# ATSAMC21N18A register map
Registers are 32-bit, access not given, no defined reset value unless marked. A register's access mark holds for its fields unless they carry their own. Addresses are absolute; registers are grouped by the start of their names; [hi:lo] are bit positions; {n}, {i} and the like mark numbered series; 'fields as' and 'values as' point back to an identical list.

## TC7
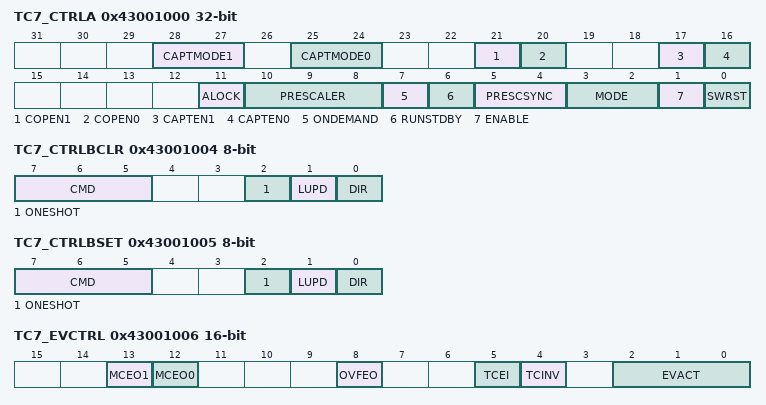
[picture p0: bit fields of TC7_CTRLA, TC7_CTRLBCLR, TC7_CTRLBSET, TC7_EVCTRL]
0x43001000 TC7_CTRLA — Control A
  [28:27] CAPTMODE1, [25:24] CAPTMODE0, [21] COPEN1, [20] COPEN0, [17] CAPTEN1, [16] CAPTEN0, [11] ALOCK, [10:8] PRESCALER, [7] ONDEMAND, [6] RUNSTDBY, [5:4] PRESCSYNC, [3:2] MODE, [1] ENABLE, [0] SWRST
0x43001004 TC7_CTRLBCLR 8-bit — Control B Clear
  [7:5] CMD, [2] ONESHOT, [1] LUPD, [0] DIR
0x43001005 TC7_CTRLBSET 8-bit — Control B Set
  [7:5] CMD, [2] ONESHOT, [1] LUPD, [0] DIR
0x43001006 TC7_EVCTRL 16-bit — Event Control
  [13] MCEO1, [12] MCEO0, [8] OVFEO, [5] TCEI, [4] TCINV, [2:0] EVACT
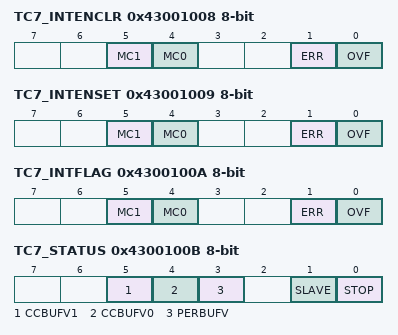
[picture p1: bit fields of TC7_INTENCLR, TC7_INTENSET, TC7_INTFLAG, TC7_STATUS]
0x43001008 TC7_INTENCLR 8-bit — Interrupt Enable Clear
  [5] MC1, [4] MC0, [1] ERR, [0] OVF
0x43001009 TC7_INTENSET 8-bit — Interrupt Enable Set
  [5] MC1, [4] MC0, [1] ERR, [0] OVF
0x4300100A TC7_INTFLAG 8-bit — Interrupt Flag Status and Clear
  [5] MC1, [4] MC0, [1] ERR, [0] OVF
0x4300100B TC7_STATUS 8-bit — Status
  [5] CCBUFV1, [4] CCBUFV0, [3] PERBUFV, [1] SLAVE, [0] STOP
0x4300100C TC7_WAVE 8-bit — Waveform Generation Control
  [1:0] WAVEGEN
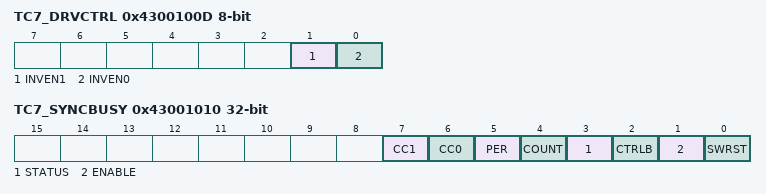
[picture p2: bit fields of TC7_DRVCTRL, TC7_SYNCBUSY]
0x4300100D TC7_DRVCTRL 8-bit — Control C
  [1] INVEN1, [0] INVEN0
0x4300100F TC7_DBGCTRL 8-bit — Debug Control
  [0] DBGRUN
0x43001010 TC7_SYNCBUSY — Synchronization Status
  [7] CC1, [6] CC0, [5] PER, [4] COUNT, [3] STATUS, [2] CTRLB, [1] ENABLE, [0] SWRST
0x43001014 TC7_COUNT_COUNT8 8-bit — COUNT8 Count
  [7:0] COUNT — Counter Value
0x43001014 TC7_COUNT_COUNT16 16-bit — COUNT16 Count
  [15:0] COUNT — Counter Value
0x43001014 TC7_COUNT_COUNT32 — COUNT32 Count
  [31:0] COUNT — Counter Value
0x4300101B TC7_PER_COUNT8 8-bit — COUNT8 Period
  [7:0] PER — Period Value
0x4300101C TC7_CC_COUNT8 8-bit — COUNT8 Compare and Capture
  [7:0] CC — Counter/Compare Value
0x4300101C TC7_CC_COUNT16 16-bit — COUNT16 Compare and Capture
  [15:0] CC — Counter/Compare Value
0x4300101C TC7_CC_COUNT32 — COUNT32 Compare and Capture
  [31:0] CC — Counter/Compare Value
0x4300102F TC7_PERBUF_COUNT8 8-bit — COUNT8 Period Buffer
  [7:0] PERBUF — Period Buffer Value
0x43001030 TC7_CCBUF_COUNT8 8-bit — COUNT8 Compare and Capture Buffer
  [7:0] CCBUF — Counter/Compare Buffer Value
0x43001030 TC7_CCBUF_COUNT16 16-bit — COUNT16 Compare and Capture Buffer
  [15:0] CCBUF — Counter/Compare Buffer Value
0x43001030 TC7_CCBUF_COUNT32 — COUNT32 Compare and Capture Buffer
  [31:0] CCBUF — Counter/Compare Buffer Value

## TCC0
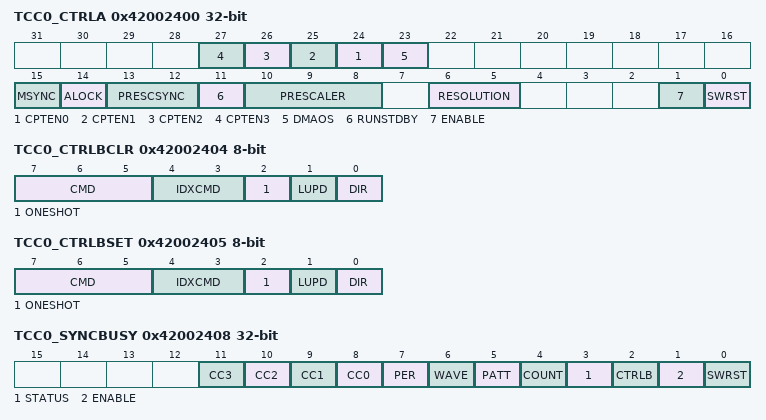
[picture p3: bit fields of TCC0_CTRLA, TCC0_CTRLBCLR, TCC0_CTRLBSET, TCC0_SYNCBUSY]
0x42002400 TCC0_CTRLA — Control A
  [n+24] CPTEN{n} (n=0..3), [23] DMAOS, [15] MSYNC, [14] ALOCK, [13:12] PRESCSYNC, [11] RUNSTDBY, [10:8] PRESCALER, [6:5] RESOLUTION, [1] ENABLE, [0] SWRST
0x42002404 TCC0_CTRLBCLR 8-bit — Control B Clear
  [7:5] CMD, [4:3] IDXCMD, [2] ONESHOT, [1] LUPD, [0] DIR
0x42002405 TCC0_CTRLBSET 8-bit — Control B Set
  [7:5] CMD, [4:3] IDXCMD, [2] ONESHOT, [1] LUPD, [0] DIR
0x42002408 TCC0_SYNCBUSY — Synchronization Busy
  [n+8] CC{n} (n=0..3), [7] PER, [6] WAVE, [5] PATT, [4] COUNT, [3] STATUS, [2] CTRLB, [1] ENABLE, [0] SWRST
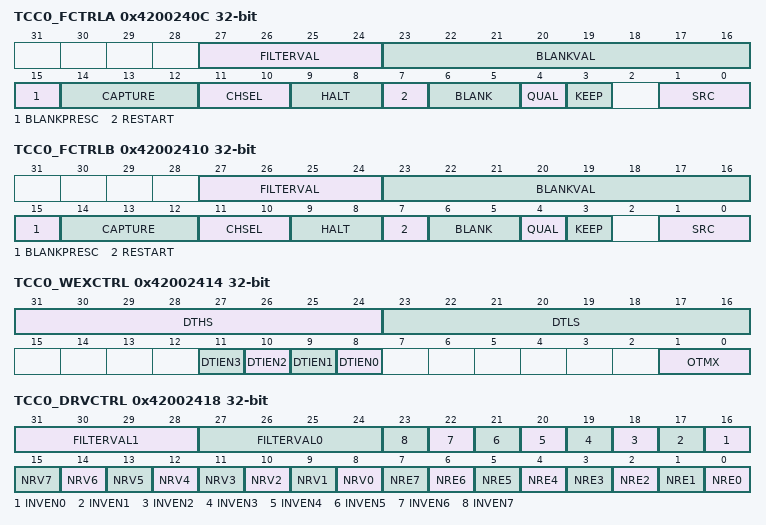
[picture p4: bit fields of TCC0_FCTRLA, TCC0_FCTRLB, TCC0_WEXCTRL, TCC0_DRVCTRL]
0x4200240C TCC0_FCTRLA — Recoverable Fault A Configuration
  [27:24] FILTERVAL, [23:16] BLANKVAL, [15] BLANKPRESC, [14:12] CAPTURE, [11:10] CHSEL, [9:8] HALT, [7] RESTART, [6:5] BLANK, [4] QUAL, [3] KEEP, [1:0] SRC
0x42002410 TCC0_FCTRLB — Recoverable Fault B Configuration
  fields as TCC0_FCTRLA
0x42002414 TCC0_WEXCTRL — Waveform Extension Configuration
  [31:24] DTHS, [23:16] DTLS, [n+8] DTIEN{n} (n=0..3), [1:0] OTMX
0x42002418 TCC0_DRVCTRL — Driver Control
  [31:28] FILTERVAL1, [27:24] FILTERVAL0, [n+16] INVEN{n} (n=0..7), [n+8] NRV{n} (n=0..7), [n] NRE{n} (n=0..7)
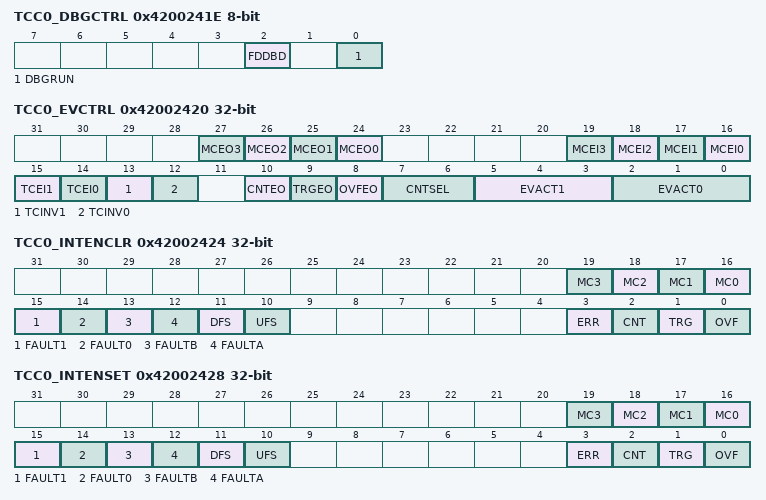
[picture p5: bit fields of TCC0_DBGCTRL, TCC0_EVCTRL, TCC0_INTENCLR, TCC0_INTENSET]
0x4200241E TCC0_DBGCTRL 8-bit — Debug Control
  [2] FDDBD, [0] DBGRUN
0x42002420 TCC0_EVCTRL — Event Control
  [n+24] MCEO{n} (n=0..3), [n+16] MCEI{n} (n=0..3), [15] TCEI1, [14] TCEI0, [13] TCINV1, [12] TCINV0, [10] CNTEO, [9] TRGEO, [8] OVFEO, [7:6] CNTSEL, [5:3] EVACT1, [2:0] EVACT0
0x42002424 TCC0_INTENCLR — Interrupt Enable Clear
  [n+16] MC{n} (n=0..3), [15] FAULT1, [14] FAULT0, [13] FAULTB, [12] FAULTA, [11] DFS, [10] UFS, [3] ERR, [2] CNT, [1] TRG, [0] OVF
0x42002428 TCC0_INTENSET — Interrupt Enable Set
  fields as TCC0_INTENCLR
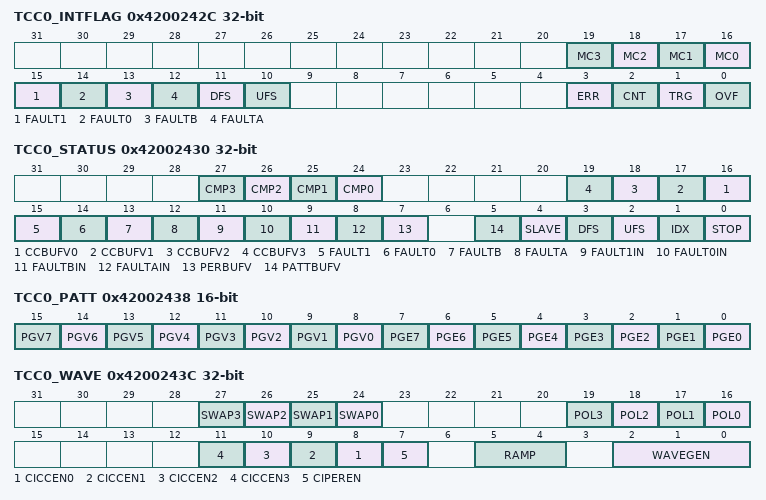
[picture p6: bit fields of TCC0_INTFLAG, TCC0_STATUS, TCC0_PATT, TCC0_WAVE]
0x4200242C TCC0_INTFLAG — Interrupt Flag Status and Clear
  fields as TCC0_INTENCLR
0x42002430 TCC0_STATUS — Status
  [n+24] CMP{n} (n=0..3), [n+16] CCBUFV{n} (n=0..3), [15] FAULT1, [14] FAULT0, [13] FAULTB, [12] FAULTA, [11] FAULT1IN, [10] FAULT0IN, [9] FAULTBIN, [8] FAULTAIN, [7] PERBUFV, [5] PATTBUFV, [4] SLAVE, [3] DFS, [2] UFS, [1] IDX, [0] STOP
0x42002434 TCC0_COUNT — Count
  [23:6] COUNT, [23:5] COUNT, [23:4] COUNT, [23:0] COUNT
0x42002438 TCC0_PATT 16-bit — Pattern
  [n+8] PGV{n} (n=0..7), [n] PGE{n} (n=0..7)
0x4200243C TCC0_WAVE — Waveform Control
  [n+24] SWAP{n} (n=0..3), [n+16] POL{n} (n=0..3), [n+8] CICCEN{n} (n=0..3), [7] CIPEREN, [5:4] RAMP, [2:0] WAVEGEN
0x42002440 TCC0_PER — Period
  [23:6] PER, [23:5] PER, [23:4] PER, [3:0] DITHER, [4:0] DITHER, [5:0] DITHER, [23:0] PER
0x42002444 TCC0_CC — Compare and Capture
  [23:6] CC, [23:5] CC, [23:4] CC, [3:0] DITHER, [4:0] DITHER, [5:0] DITHER, [23:0] CC
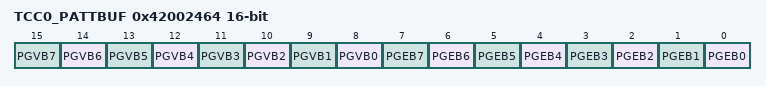
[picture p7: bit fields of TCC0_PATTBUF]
0x42002464 TCC0_PATTBUF 16-bit — Pattern Buffer
  [n+8] PGVB{n} (n=0..7), [n] PGEB{n} (n=0..7)
0x4200246C TCC0_PERBUF — Period Buffer
  [23:6] PERBUF, [23:5] PERBUF, [23:4] PERBUF, [3:0] DITHERBUF, [4:0] DITHERBUF, [5:0] DITHERBUF, [23:0] PERBUF
0x42002470 TCC0_CCBUF — Compare and Capture Buffer
  [23:6] CCBUF, [23:5] CCBUF, [23:4] DITHERBUF, [3:0] CCBUF, [4:0] DITHERBUF, [5:0] DITHERBUF, [23:0] CCBUF
